AUTOSAR XML (schema 4-0-3)
package /ComponentTypes
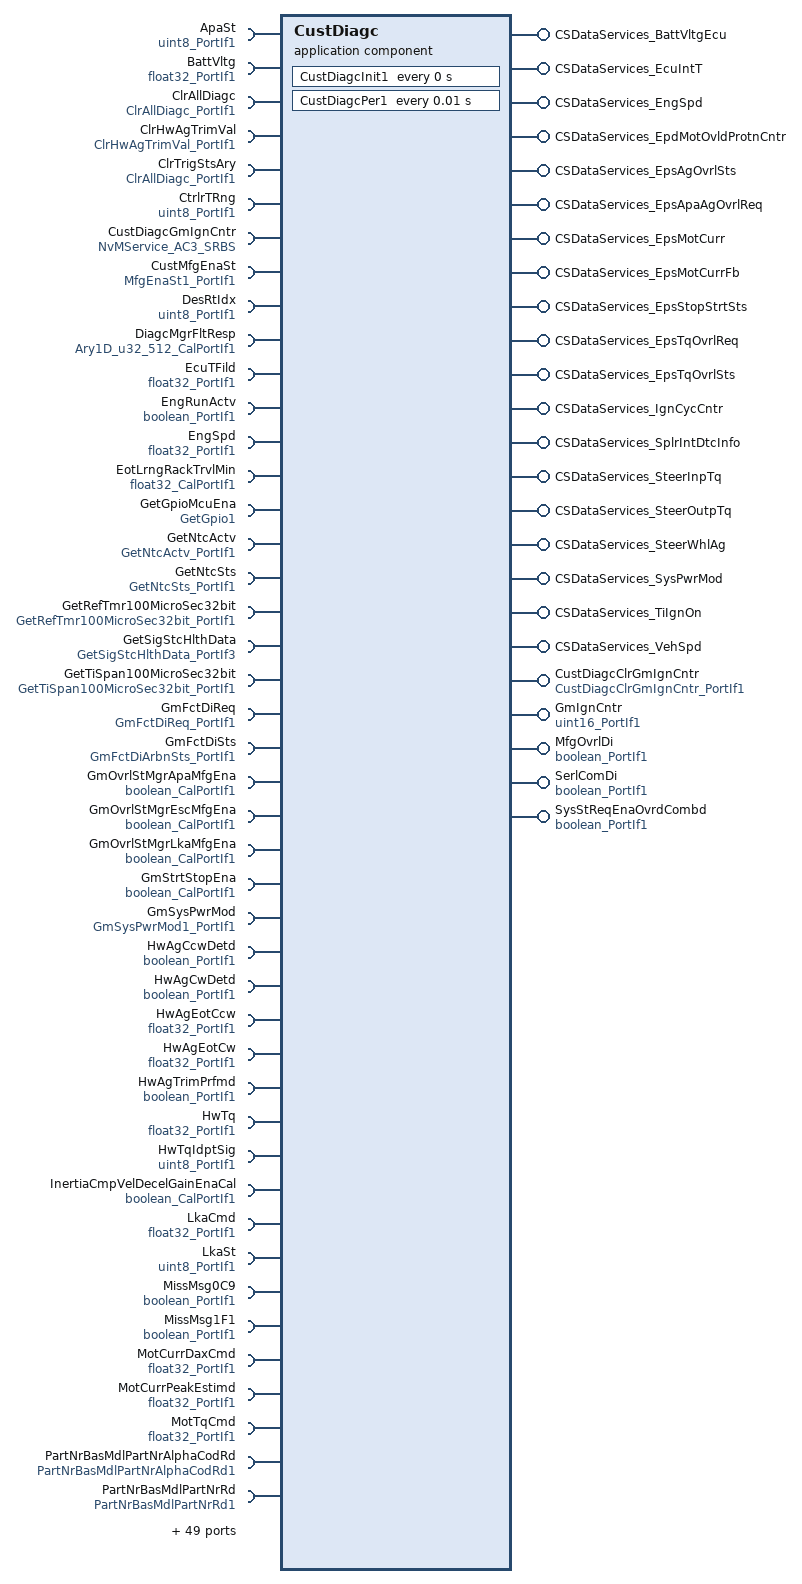
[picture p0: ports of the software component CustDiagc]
  application sw component type CustDiagc
    24 x provide port:
      CSDataServices_BattVltgEcu: server-com-spec{operation=ReadData, queue-length=1}, provided-interface=CSDataServices_BattVltgEcu
      CSDataServices_EcuIntT: server-com-spec{operation=ReadData, queue-length=1}, provided-interface=CSDataServices_EcuIntT
      CSDataServices_EngSpd: server-com-spec{operation=ReadData, queue-length=1}, provided-interface=CSDataServices_EngSpd
      CSDataServices_EpdMotOvldProtnCntr: server-com-spec{operation=ReadData, queue-length=1}, provided-interface=CSDataServices_EpdMotOvldProtnCntr
      CSDataServices_EpsAgOvrlSts: server-com-spec{operation=ReadData, queue-length=1}, provided-interface=CSDataServices_EpsAgOvrlSts
      CSDataServices_EpsApaAgOvrlReq: server-com-spec{operation=ReadData, queue-length=1}, provided-interface=CSDataServices_EpsApaAgOvrlReq
      CSDataServices_EpsMotCurr: server-com-spec{operation=ReadData, queue-length=1}, provided-interface=CSDataServices_EpsMotCurr
      CSDataServices_EpsMotCurrFb: server-com-spec{operation=ReadData, queue-length=1}, provided-interface=CSDataServices_EpsMotCurrFb
      CSDataServices_EpsStopStrtSts: server-com-spec{operation=ReadData, queue-length=1}, provided-interface=CSDataServices_EpsStopStrtSts
      CSDataServices_EpsTqOvrlReq: server-com-spec{operation=ReadData, queue-length=1}, provided-interface=CSDataServices_EpsTqOvrlReq
      CSDataServices_EpsTqOvrlSts: server-com-spec{operation=ReadData, queue-length=1}, provided-interface=CSDataServices_EpsTqOvrlSts
      CSDataServices_IgnCycCntr: server-com-spec{operation=ReadData, queue-length=1}, provided-interface=CSDataServices_IgnCycCntr
      CSDataServices_SplrIntDtcInfo: server-com-spec{operation=ReadData, queue-length=1}, provided-interface=CSDataServices_SplrIntDtcInfo
      CSDataServices_SteerInpTq: server-com-spec{operation=ReadData, queue-length=1}, provided-interface=CSDataServices_SteerInpTq
      CSDataServices_SteerOutpTq: server-com-spec{operation=ReadData, queue-length=1}, provided-interface=CSDataServices_SteerOutpTq
      CSDataServices_SteerWhlAg: server-com-spec{operation=ReadData, queue-length=1}, provided-interface=CSDataServices_SteerWhlAg
      CSDataServices_SysPwrMod: server-com-spec{operation=ReadData, queue-length=1}, provided-interface=CSDataServices_SysPwrMod
      CSDataServices_TiIgnOn: server-com-spec{operation=ReadData, queue-length=1}, provided-interface=CSDataServices_TiIgnOn
      CSDataServices_VehSpd: server-com-spec{operation=ReadData, queue-length=1}, provided-interface=CSDataServices_VehSpd
      CustDiagcClrGmIgnCntr: server-com-spec{operation=Oper, queue-length=1}, provided-interface=CustDiagcClrGmIgnCntr_PortIf1
      GmIgnCntr: nonqueued-sender-com-spec{data-element=Val, init-value=0}, provided-interface=uint16_PortIf1
      MfgOvrlDi: nonqueued-sender-com-spec{data-element=Logl, init-value=0}, provided-interface=boolean_PortIf1
      SerlComDi: nonqueued-sender-com-spec{data-element=Logl, init-value=0}, provided-interface=boolean_PortIf1
      SysStReqEnaOvrdCombd: nonqueued-sender-com-spec{data-element=Logl, init-value=0}, provided-interface=boolean_PortIf1
    93 x require port:
      ApaSt: nonqueued-receiver-com-spec{data-element=Val, filter=data-filter-type=ALWAYS, init-value=0}, required-interface=uint8_PortIf1
      BattVltg: nonqueued-receiver-com-spec{data-element=Val, filter=data-filter-type=ALWAYS, init-value=0}, required-interface=float32_PortIf1
      ClrAllDiagc: required-interface=ClrAllDiagc_PortIf1
      ClrHwAgTrimVal: required-interface=ClrHwAgTrimVal_PortIf1
      ClrTrigStsAry: required-interface=ClrAllDiagc_PortIf1
      CtrlrTRng: nonqueued-receiver-com-spec{data-element=Val, filter=data-filter-type=ALWAYS, init-value=0}, required-interface=uint8_PortIf1
      CustDiagcGmIgnCntr: required-interface=NvMService_AC3_SRBS
      CustMfgEnaSt: nonqueued-receiver-com-spec{data-element=Val, filter=data-filter-type=ALWAYS, init-value=0}, required-interface=MfgEnaSt1_PortIf1
      DesRtIdx: nonqueued-receiver-com-spec{data-element=Val, filter=data-filter-type=ALWAYS, init-value=0}, required-interface=uint8_PortIf1
      DiagcMgrFltResp: parameter-require-com-spec{init-value=[0, 2147487488, 2147487488, 2147487488, 2147487488, 2147487488, 2147487488, 2147487488, 2147487488, 2147487488, 2147487488, 2147487488, 2147487488, 2147487488, 2147487488, 2147487488, 2147487488, 2147487488, 2147487488, 2147487488, 2147487488, 2147487488, 2147487488, 2147487488, 2147487488, 2147487488, 2147487488, 2147487488, 2147487488, 2147487488, 2147487488, 2147487488, 2147487488, 2147487488, 2147487488, 2147487488, 2147487488, 2147487488, 2147487488, 2147487488, 2147487488, 2147487488, 2147487488, 2147487488, 2147487488, 2147487488, 2147487488, 2147487488, 2147487488, 2147487488, 2147487488, 2147487488, 2147487488, 2147487488, 2147487488, 2147487488, 2147487488, 2147487488, 2147487488, 2147487488, 2147487488, 2147487488, 2147487488, 2147487488, 2147487488, 2147487488, 2147487488, 2147487488, 2147487488, 2147487488, 2147487488, 2147487488, 2147487488, 2147487488, 2147487488, 2147487488, 2147487488, 2147487488, 2147487488, 2147487488, 2147487488, 2147487488, 2147487488, 2147487488, 2147487488, 2147487488, 2147487488, 2147487488, 2147487488, 2147487488, 2147487488, 2147487488, 2147487488, 2147487488, 2147487488, 2147487488, 2147487488, 2147487488, 2147487488, 2147487488, 2147487488, 2147487488, 2147487488, 2147487488, 2147487488, 2147487488, 2147487488, 2147487488, 2147487488, 2147487488, 2147487488, 2147487488, 2147487488, 2147487488, 2147487488, 2147487488, 2147487488, 2147487488, 2147487488, 2147487488, 2147487488, 2147487488, 2147487488, 2147487488, 2147487488, 2147487488, 2147487488, 2147487488, 2147487488, 2147487488, 2147487488, 2147487488, 2147487488, 2147487488, 2147487488, 2147487488, 2147487488, 2147487488, 2147487488, 2147487488, 2147487488, 2147487488, 2147487488, 2147487488, 2147487488, 2147487488, 2147487488, 2147487488, 2147487488, 2147487488, 2147487488, 2147487488, 2147487488, 2147487488, 2147487488, 2147487488, 2147487488, 2147487488, 2147487488, 2147487488, 2147487488, 2147487488, 2147487488, 2147487488, 2147487488, 2147487488, 2147487488, 2147487488, 2147487488, 2147487488, 2147487488, 2147487488, 2147487488, 2147487488, 2147487488, 2147487488, 2147487488, 2147487488, 2147487488, 2147487488, 2147487488, 2147487488, 2147487488, 2147487488, 2147487488, 2147487488, 2147487488, 2147487488, 2147487488, 2147487488, 2147487488, 2147487488, 2147487488, 2147487488, 2147487488, 2147487488, 2147487488, 2147487488, 2147487488, 2147487488, 2147487488, 2147487488, 2147487488, 2147487488, 2147487488, 2147487488, 2147487488, 2147487488, 2147487488, 2147487488, 2147487488, 2147487488, 2147487488, 2147487488, 2147487488, 2147487488, 2147487488, 2147487488, 2147487488, 2147487488, 2147487488, 2147487488, 2147487488, 2147487488, 2147487488, 2147487488, 2147487488, 2147487488, 2147487488, 2147487488, 2147487488, 2147487488, 2147487488, 2147487488, 2147487488, 2147487488, 2147487488, 2147487488, 2147487488, 2147487488, 2147487488, 2147487488, 2147487488, 2147487488, 2147487488, 2147487488, 2147487488, 2147487488, 2147487488, 2147487488, 2147487488, 2147487488, 2147487488, 2147487488, 2147487488, 2147487488, 2147487488, 2147487488, 2147487488, 2147487488, 2147487488, 2147487488, 2147487488, 2147487488, 2147487488, 2147487488, 2147487488, 2147487488, 2147487488, 2147487488, 2147487488, 2147487488, 2147487488, 2147487488, 2147487488, 2147487488, 2147487488, 2147487488, 2147487488, 2147487488, 2147487488, 2147487488, 2147487488, 2147487488, 2147487488, 2147487488, 2147487488, 2147487488, 2147487488, 2147487488, 2147487488, 2147487488, 2147487488, 2147487488, 2147487488, 2147487488, 2147487488, 2147487488, 2147487488, 2147487488, 2147487488, 2147487488, 2147487488, 2147487488, 2147487488, 2147487488, 2147487488, 2147487488, 2147487488, 2147487488, 2147487488, 2147487488, 2147487488, 2147487488, 2147487488, 2147487488, 2147487488, 2147487488, 2147487488, 2147487488, 2147487488, 2147487488, 2147487488, 2147487488, 2147487488, 2147487488, 2147487488, 2147487488, 2147487488, 2147487488, 2147487488, 2147487488, 2147487488, 2147487488, 2147487488, 2147487488, 2147487488, 2147487488, 2147487488, 2147487488, 2147487488, 2147487488, 2147487488, 2147487488, 2147487488, 2147487488, 2147487488, 2147487488, 2147487488, 2147487488, 2147487488, 2147487488, 2147487488, 2147487488, 2147487488, 2147487488, 2147487488, 2147487488, 2147487488, 2147487488, 2147487488, 2147487488, 2147487488, 2147487488, 2147487488, 2147487488, 2147487488, 2147487488, 2147487488, 2147487488, 2147487488, 2147487488, 2147487488, 2147487488, 2147487488, 2147487488, 2147487488, 2147487488, 2147487488, 2147487488, 2147487488, 2147487488, 2147487488, 2147487488, 2147487488, 2147487488, 2147487488, 2147487488, 2147487488, 2147487488, 2147487488, 2147487488, 2147487488, 2147487488, 2147487488, 2147487488, 2147487488, 2147487488, 2147487488, 2147487488, 2147487488, 2147487488, 2147487488, 2147487488, 2147487488, 2147487488, 2147487488, 2147487488, 2147487488, 2147487488, 2147487488, 2147487488, 2147487488, 2147487488, 2147487488, 2147487488, 2147487488, 2147487488, 2147487488, 2147487488, 2147487488, 2147487488, 2147487488, 2147487488, 2147487488, 2147487488, 2147487488, 2147487488, 2147487488, 2147487488, 2147487488, 2147487488, 2147487488, 2147487488, 2147487488, 2147487488, 2147487488, 2147487488, 2147487488, 2147487488, 2147487488, 2147487488, 2147487488, 2147487488, 2147487488, 2147487488, 2147487488, 2147487488, 2147487488, 2147487488, 2147487488, 2147487488, 2147487488, 2147487488, 2147487488, 2147487488, 2147487488, 2147487488, 2147487488, 2147487488, 2147487488, 2147487488, 2147487488, 2147487488, 2147487488, 2147487488, 2147487488, 2147487488, 2147487488, 2147487488, 2147487488, 2147487488, 2147487488, 2147487488, 2147487488, 2147487488, 2147487488, 2147487488, 2147487488, 2147487488, 2147487488, 2147487488, 2147487488, 2147487488, 2147487488, 2147487488, 2147487488, 2147487488, 2147487488, 2147487488, 2147487488, 2147487488, 2147487488, 2147487488, 2147487488, 2147487488, 2147487488, 2147487488, 2147487488, 2147487488, 2147487488, 2147487488, 2147487488, 2147487488, 2147487488, 2147487488, 2147487488, 2147487488, 2147487488, 2147487488, 2147487488, 2147487488], parameter=Ary1D}, required-interface=Ary1D_u32_512_CalPortIf1
      EcuTFild: nonqueued-receiver-com-spec{data-element=Val, filter=data-filter-type=ALWAYS, init-value=0}, required-interface=float32_PortIf1
      EngRunActv: nonqueued-receiver-com-spec{data-element=Logl, filter=data-filter-type=ALWAYS, init-value=0}, required-interface=boolean_PortIf1
      EngSpd: nonqueued-receiver-com-spec{data-element=Val, filter=data-filter-type=ALWAYS, init-value=0}, required-interface=float32_PortIf1
      EotLrngRackTrvlMin: parameter-require-com-spec{init-value=400, parameter=Val}, required-interface=float32_CalPortIf1
      GetGpioMcuEna: required-interface=GetGpio1
      GetNtcActv: required-interface=GetNtcActv_PortIf1
      GetNtcSts: required-interface=GetNtcSts_PortIf1
      GetRefTmr100MicroSec32bit: required-interface=GetRefTmr100MicroSec32bit_PortIf1
      GetSigStcHlthData: required-interface=GetSigStcHlthData_PortIf3
      GetTiSpan100MicroSec32bit: required-interface=GetTiSpan100MicroSec32bit_PortIf1
      GmFctDiReq: required-interface=GmFctDiReq_PortIf1
      GmFctDiSts: nonqueued-receiver-com-spec{data-element=Val, filter=data-filter-type=ALWAYS, init-value=0}, required-interface=GmFctDiArbnSts_PortIf1
      GmOvrlStMgrApaMfgEna: parameter-require-com-spec{init-value=0, parameter=Logl}, required-interface=boolean_CalPortIf1
      GmOvrlStMgrEscMfgEna: parameter-require-com-spec{init-value=0, parameter=Logl}, required-interface=boolean_CalPortIf1
      GmOvrlStMgrLkaMfgEna: parameter-require-com-spec{init-value=0, parameter=Logl}, required-interface=boolean_CalPortIf1
      GmStrtStopEna: parameter-require-com-spec{init-value=1, parameter=Logl}, required-interface=boolean_CalPortIf1
      GmSysPwrMod: nonqueued-receiver-com-spec{data-element=Val, filter=data-filter-type=ALWAYS, init-value=0}, required-interface=GmSysPwrMod1_PortIf1
      HwAgCcwDetd: nonqueued-receiver-com-spec{data-element=Logl, filter=data-filter-type=ALWAYS, init-value=0}, required-interface=boolean_PortIf1
      HwAgCwDetd: nonqueued-receiver-com-spec{data-element=Logl, filter=data-filter-type=ALWAYS, init-value=0}, required-interface=boolean_PortIf1
      HwAgEotCcw: nonqueued-receiver-com-spec{data-element=Val, filter=data-filter-type=ALWAYS, init-value=-360}, required-interface=float32_PortIf1
      HwAgEotCw: nonqueued-receiver-com-spec{data-element=Val, filter=data-filter-type=ALWAYS, init-value=360}, required-interface=float32_PortIf1
      HwAgTrimPrfmd: nonqueued-receiver-com-spec{data-element=Logl, filter=data-filter-type=ALWAYS, init-value=0}, required-interface=boolean_PortIf1
      HwTq: nonqueued-receiver-com-spec{data-element=Val, filter=data-filter-type=ALWAYS, init-value=0}, required-interface=float32_PortIf1
      HwTqIdptSig: nonqueued-receiver-com-spec{data-element=Val, filter=data-filter-type=ALWAYS, init-value=4}, required-interface=uint8_PortIf1
      InertiaCmpVelDecelGainEnaCal: parameter-require-com-spec{init-value=0, parameter=Logl}, required-interface=boolean_CalPortIf1
      LkaCmd: nonqueued-receiver-com-spec{data-element=Val, filter=data-filter-type=ALWAYS, init-value=0}, required-interface=float32_PortIf1
      LkaSt: nonqueued-receiver-com-spec{data-element=Val, filter=data-filter-type=ALWAYS, init-value=0}, required-interface=uint8_PortIf1
      MissMsg0C9: nonqueued-receiver-com-spec{data-element=Logl, filter=data-filter-type=ALWAYS, init-value=0}, required-interface=boolean_PortIf1
      MissMsg1F1: nonqueued-receiver-com-spec{data-element=Logl, filter=data-filter-type=ALWAYS, init-value=0}, required-interface=boolean_PortIf1
      MotCurrDaxCmd: nonqueued-receiver-com-spec{data-element=Val, filter=data-filter-type=ALWAYS, init-value=0}, required-interface=float32_PortIf1
      MotCurrPeakEstimd: nonqueued-receiver-com-spec{data-element=Val, filter=data-filter-type=ALWAYS, init-value=0}, required-interface=float32_PortIf1
      MotTqCmd: nonqueued-receiver-com-spec{data-element=Val, filter=data-filter-type=ALWAYS, init-value=0}, required-interface=float32_PortIf1
      PartNrBasMdlPartNrAlphaCodRd: required-interface=PartNrBasMdlPartNrAlphaCodRd1
      PartNrBasMdlPartNrRd: required-interface=PartNrBasMdlPartNrRd1
      PartNrCalProgdStsRd: required-interface=PartNrCalProgdStsRd1
      PartNrCalProgdStsWr: required-interface=PartNrCalProgdStsWr1
      PartNrCcaMfgTrakgRd: required-interface=PartNrCcaMfgTrakgRd1
      PartNrCmpdVehPartnProdtStructRd: required-interface=PartNrCmpdVehPartnProdtStructRd1
      PartNrCtrlPidKeyChk: required-interface=PartNrCtrlPidKeyChk1
      PartNrCtrlPidKeyWr: required-interface=PartNrCtrlPidKeyWr1
      PartNrCtrlPidSeedRd: required-interface=PartNrCtrlPidSeedRd1
      PartNrCtrlPidSeedUpprByteWr: required-interface=PartNrCtrlPidSeedUpprByteWr1
      PartNrCustMfgEnaCntrRd: required-interface=PartNrCustMfgEnaCntrRd1
      PartNrCustMfgEnaCntrWr: required-interface=PartNrCustMfgEnaCntrWr1
      PartNrDataUniversalNrSysIdRd: required-interface=PartNrDataUniversalNrSysIdRd1
      PartNrEcuIdRd: required-interface=PartNrEcuIdRd_PortIf1
      PartNrEndMdlPartNrAlphaCodRd: required-interface=PartNrEndMdlPartNrAlphaCodRd1
      PartNrEndMdlPartNrAlphaCodWr: required-interface=PartNrEndMdlPartNrAlphaCodWr1
      PartNrEndMdlPartNrRd: required-interface=PartNrEndMdlPartNrRd1
      PartNrEndMdlPartNrWr: required-interface=PartNrEndMdlPartNrWr1
      PartNrGmLanIdRd: required-interface=PartNrGmLanIdRd1
      PartNrLstRepairShopCodRd: required-interface=PartNrLstRepairShopCodRd1
      PartNrNxtrMfgTrakgRd: required-interface=PartNrNxtrMfgTrakgRd1
      PartNrNxtrMfgTrakgWr: required-interface=PartNrNxtrMfgTrakgWr1
      PartNrProgmDateRd: required-interface=PartNrProgmDateRd1
      PartNrProgmDateWr: required-interface=PartNrProgmDateWr1
      PartNrProgmSessionKeyChk: required-interface=PartNrProgmSessionKeyChk1
      PartNrProgmSessionSeedRd: required-interface=PartNrProgmSessionSeedRd1
      PartNrRepairShopCodRd: required-interface=PartNrRepairShopCodRd1
      PartNrRepairShopCodWr: required-interface=PartNrRepairShopCodWr1
      PartNrSecuBypAuthnRd: required-interface=PartNrSecuBypAuthnRd_PortIf1
      PartNrSecuBypAuthnWr: required-interface=PartNrSecuBypAuthnWr_PortIf1
      PartNrSysCodVersNrRd: required-interface=PartNrSysCodVersNrRd1
      PartNrSysCodVersNrWr: required-interface=PartNrSysCodVersNrWr1
      PartNrSysNameRd: required-interface=PartNrSysNameRd1
      PartNrSysNameWr: required-interface=PartNrSysNameWr1
      PartNrVinDataRd: required-interface=PartNrVinDataRd1
      PartNrVinDataWr: required-interface=PartNrVinDataWr1
      PinionAg: nonqueued-receiver-com-spec{data-element=Val, filter=data-filter-type=ALWAYS, init-value=0}, required-interface=float32_PortIf1
      PinionAgConf: nonqueued-receiver-com-spec{data-element=Val, filter=data-filter-type=ALWAYS, init-value=0}, required-interface=float32_PortIf1
      PullCmpActvEna: parameter-require-com-spec{init-value=1, parameter=Logl}, required-interface=boolean_CalPortIf1
      RtnMaxHwAgCwAndCcw: required-interface=RtnMaxHwAgCwAndCcw_PortIf1
      SteerWhlAgReqTarAg: nonqueued-receiver-com-spec{data-element=Val, filter=data-filter-type=ALWAYS, init-value=0}, required-interface=float32_PortIf1
      StrtStopSt: nonqueued-receiver-com-spec{data-element=Val, filter=data-filter-type=ALWAYS, init-value=0}, required-interface=uint8_PortIf1
      SysPwrMod: nonqueued-receiver-com-spec{data-element=Val, filter=data-filter-type=ALWAYS, init-value=0}, required-interface=GmSysPwrMod1_PortIf1
      SysSt: nonqueued-receiver-com-spec{data-element=Val, filter=data-filter-type=ALWAYS, init-value=3}, required-interface=SysSt1
      SysStReqEnaOvrdNxtr: nonqueued-receiver-com-spec{data-element=Logl, filter=data-filter-type=ALWAYS, init-value=0}, required-interface=boolean_PortIf1
      ThermLimFlgCntr: nonqueued-receiver-com-spec{data-element=Val, filter=data-filter-type=ALWAYS, init-value=0}, required-interface=uint8_PortIf1
      UpdHwAgTrimVal: required-interface=UpdHwAgTrimVal_PortIf1
      VehSpd: nonqueued-receiver-com-spec{data-element=Val, filter=data-filter-type=ALWAYS, init-value=0}, required-interface=float32_PortIf1
      VehSpdVld: nonqueued-receiver-com-spec{data-element=Logl, filter=data-filter-type=ALWAYS, init-value=0}, required-interface=boolean_PortIf1
      VltgRng: nonqueued-receiver-com-spec{data-element=Val, filter=data-filter-type=ALWAYS, init-value=0}, required-interface=uint8_PortIf1
      WhlImbRejctnFctEna: parameter-require-com-spec{init-value=1, parameter=Logl}, required-interface=boolean_CalPortIf1
    behavior CustDiagc_InternalBehavior: data-type-mapping=Nexteer
      ar-typed-per-instance-memorys:
        18 x data, all with sw-calibration-access=READ-ONLY:
          CpidActv: type=boolean
          CustDiagcCtrlPidKeyAtmptCntr: type=uint8
          CustDiagcCtrlPidSeedKeyTmr: type=uint32
          CustDiagcCtrlPidSeedReqd: type=boolean
          CustDiagcCtrlPidSeedTmrActvd: type=boolean
          CustDiagcProgmSessionKeyAtmptCntr: type=uint8
          CustDiagcProgmSessionSeedKeyTmr: type=uint32
          CustDiagcProgmSessionSeedReqd: type=boolean
          CustDiagcProgmSessionSeedTmrActvd: type=boolean
          DtcNr: type=uint32
          GmDiCtrlPidTstRunng: type=boolean
          GmIgnCntr: type=uint16
          MsgCntxt: type=uint32
          PrevGmFctDiArbnSts: type=GmFctDiArbnSts1
          PrevSysPwrModRun: type=boolean
          Srv12LoopCntr: type=uint8
          SrvCntxt: type=uint8
          SysStReqEnaOvrdCust: type=boolean
      20 x operation invoked event:
        OIT_CSDataServices_BattVltgEcu_ReadData_CSDataServices_BattVltgEcu_ReadData: start-on-event=CSDataServices_BattVltgEcu_ReadData, operation=CSDataServices_BattVltgEcu.ReadData
        OIT_CSDataServices_EcuIntT_ReadData_CSDataServices_EcuIntT_ReadData: start-on-event=CSDataServices_EcuIntT_ReadData, operation=CSDataServices_EcuIntT.ReadData
        OIT_CSDataServices_EngSpd_ReadData_CSDataServices_EngSpd_ReadData: start-on-event=CSDataServices_EngSpd_ReadData, operation=CSDataServices_EngSpd.ReadData
        OIT_CSDataServices_EpdMotOvldProtnCntr_ReadData_CSDataServices_EpdMotOvldProtnCntr_ReadData: start-on-event=CSDataServices_EpdMotOvldProtnCntr_ReadData, operation=CSDataServices_EpdMotOvldProtnCntr.ReadData
        OIT_CSDataServices_EpsAgOvrlSts_ReadData_CSDataServices_EpsAgOvrlSts_ReadData: start-on-event=CSDataServices_EpsAgOvrlSts_ReadData, operation=CSDataServices_EpsAgOvrlSts.ReadData
        OIT_CSDataServices_EpsApaAgOvrlReq_ReadData_CSDataServices_EpsApaAgOvrlReq_ReadData: start-on-event=CSDataServices_EpsApaAgOvrlReq_ReadData, operation=CSDataServices_EpsApaAgOvrlReq.ReadData
        OIT_CSDataServices_EpsMotCurr_ReadData_CSDataServices_EpsMotCurr_ReadData: start-on-event=CSDataServices_EpsMotCurr_ReadData, operation=CSDataServices_EpsMotCurr.ReadData
        OIT_CSDataServices_EpsMotCurrFb_ReadData_CSDataServices_EpsMotCurrFb_ReadData: start-on-event=CSDataServices_EpsMotCurrFb_ReadData, operation=CSDataServices_EpsMotCurrFb.ReadData
        OIT_CSDataServices_EpsStopStrtSts_ReadData_CSDataServices_EpsStopStrtSts_ReadData: start-on-event=CSDataServices_EpsStopStrtSts_ReadData, operation=CSDataServices_EpsStopStrtSts.ReadData
        OIT_CSDataServices_EpsTqOvrlReq_ReadData_CSDataServices_EpsTqOvrlReq_ReadData: start-on-event=CSDataServices_EpsTqOvrlReq_ReadData, operation=CSDataServices_EpsTqOvrlReq.ReadData
        OIT_CSDataServices_EpsTqOvrlSts_ReadData_CSDataServices_EpsTqOvrlSts_ReadData: start-on-event=CSDataServices_EpsTqOvrlSts_ReadData, operation=CSDataServices_EpsTqOvrlSts.ReadData
        OIT_CSDataServices_IgnCycCntr_ReadData_CSDataServices_IgnCycCntr_ReadData: start-on-event=CSDataServices_IgnCycCntr_ReadData, operation=CSDataServices_IgnCycCntr.ReadData
        OIT_CSDataServices_SplrIntDtcInfo_ReadData_CSDataServices_SplrIntDtcInfo_ReadData: start-on-event=CSDataServices_SplrIntDtcInfo_ReadData, operation=CSDataServices_SplrIntDtcInfo.ReadData
        OIT_CSDataServices_SteerInpTq_ReadData_CSDataServices_SteerInpTq_ReadData: start-on-event=CSDataServices_SteerInpTq_ReadData, operation=CSDataServices_SteerInpTq.ReadData
        OIT_CSDataServices_SteerOutpTq_ReadData_CSDataServices_SteerOutpTq_ReadData: start-on-event=CSDataServices_SteerOutpTq_ReadData, operation=CSDataServices_SteerOutpTq.ReadData
        OIT_CSDataServices_SteerWhlAg_ReadData_CSDataServices_SteerWhlAg_ReadData: start-on-event=CSDataServices_SteerWhlAg_ReadData, operation=CSDataServices_SteerWhlAg.ReadData
        OIT_CSDataServices_SysPwrMod_ReadData_CSDataServices_SysPwrMod_ReadData: start-on-event=CSDataServices_SysPwrMod_ReadData, operation=CSDataServices_SysPwrMod.ReadData
        OIT_CSDataServices_TiIgnOn_ReadData_CSDataServices_TiIgnOn_ReadData: start-on-event=CSDataServices_TiIgnOn_ReadData, operation=CSDataServices_TiIgnOn.ReadData
        OIT_CSDataServices_VehSpd_ReadData_CSDataServices_VehSpd_ReadData: start-on-event=CSDataServices_VehSpd_ReadData, operation=CSDataServices_VehSpd.ReadData
        OIT_CustDiagcClrGmIgnCntr_Oper_CustDiagcClrGmIgnCntr_Oper: start-on-event=CustDiagcClrGmIgnCntr_Oper, operation=CustDiagcClrGmIgnCntr.Oper
      timing event CustDiagc_InitEvent: start-on-event=CustDiagcInit1, period=0
      timing event TMT_CustDiagcPer1: start-on-event=CustDiagcPer1, period=0.01
      22 x runnable:
        CSDataServices_BattVltgEcu_ReadData
          data-receive-point-by-arguments:
            access REC_BattVltg_Val: accessed-variable=BattVltg.Val
        CSDataServices_EcuIntT_ReadData
          data-receive-point-by-arguments:
            access REC_EcuTFild_Val: accessed-variable=EcuTFild.Val
        CSDataServices_EngSpd_ReadData
          data-receive-point-by-arguments:
            access REC_EngSpd_Val: accessed-variable=EngSpd.Val
            access REC_MissMsg0C9_Logl: accessed-variable=MissMsg0C9.Logl
        CSDataServices_EpdMotOvldProtnCntr_ReadData
          data-receive-point-by-arguments:
            access REC_ThermLimFlgCntr_Val: accessed-variable=ThermLimFlgCntr.Val
        CSDataServices_EpsAgOvrlSts_ReadData
          data-receive-point-by-arguments:
            access REC_ApaSt_Val: accessed-variable=ApaSt.Val
        CSDataServices_EpsApaAgOvrlReq_ReadData
          data-receive-point-by-arguments:
            access REC_SteerWhlAgReqTarAg_Val: accessed-variable=SteerWhlAgReqTarAg.Val
        CSDataServices_EpsMotCurr_ReadData
          data-receive-point-by-arguments:
            access REC_MotCurrDaxCmd_Val: accessed-variable=MotCurrDaxCmd.Val
        CSDataServices_EpsMotCurrFb_ReadData
          data-receive-point-by-arguments:
            access REC_MotCurrPeakEstimd_Val: accessed-variable=MotCurrPeakEstimd.Val
        CSDataServices_EpsStopStrtSts_ReadData
          data-receive-point-by-arguments:
            access REC_StrtStopSt_Val: accessed-variable=StrtStopSt.Val
        CSDataServices_EpsTqOvrlReq_ReadData
          data-receive-point-by-arguments:
            access REC_LkaCmd_Val: accessed-variable=LkaCmd.Val
        CSDataServices_EpsTqOvrlSts_ReadData
          data-receive-point-by-arguments:
            access REC_LkaSt_Val: accessed-variable=LkaSt.Val
        CSDataServices_IgnCycCntr_ReadData
        CSDataServices_SplrIntDtcInfo_ReadData
          sync call SC_GetNtcActv_Oper: operation=GetNtcActv.Oper, timeout=0
          sync call SC_GetNtcSts_Oper: operation=GetNtcSts.Oper, timeout=0
        CSDataServices_SteerInpTq_ReadData
          data-receive-point-by-arguments:
            access REC_HwTq_Val: accessed-variable=HwTq.Val
        CSDataServices_SteerOutpTq_ReadData
          data-receive-point-by-arguments:
            access REC_MotTqCmd_Val: accessed-variable=MotTqCmd.Val
        CSDataServices_SteerWhlAg_ReadData
          data-receive-point-by-arguments:
            access REC_PinionAg_Val: accessed-variable=PinionAg.Val
        CSDataServices_SysPwrMod_ReadData
          data-receive-point-by-arguments:
            access REC_GmSysPwrMod_Val: accessed-variable=GmSysPwrMod.Val
            access REC_MissMsg1F1_Logl: accessed-variable=MissMsg1F1.Logl
        CSDataServices_TiIgnOn_ReadData
          sync call SC_GetRefTmr100MicroSec32bit_Oper: operation=GetRefTmr100MicroSec32bit.Oper, timeout=0
        CSDataServices_VehSpd_ReadData
          data-receive-point-by-arguments:
            access REC_VehSpd_Val: accessed-variable=VehSpd.Val
        CustDiagcClrGmIgnCntr_Oper
          sync call SC_CustDiagcGmIgnCntr_SetRamBlockStatus: operation=CustDiagcGmIgnCntr.SetRamBlockStatus, timeout=0
        CustDiagcInit1
          data-receive-point-by-arguments:
            31 x access:
              REC_ApaSt_Val: accessed-variable=ApaSt.Val
              REC_BattVltg_Val: accessed-variable=BattVltg.Val
              REC_CtrlrTRng_Val_1: accessed-variable=CtrlrTRng.Val
              REC_DesRtIdx_Val: accessed-variable=DesRtIdx.Val
              REC_EcuTFild_Val: accessed-variable=EcuTFild.Val
              REC_EngRunActv_Logl: accessed-variable=EngRunActv.Logl
              REC_EngSpd_Val: accessed-variable=EngSpd.Val
              REC_HwAgCcwDetd_Logl: accessed-variable=HwAgCcwDetd.Logl
              REC_HwAgCwDetd_Logl: accessed-variable=HwAgCwDetd.Logl
              REC_HwAgEotCcw_Val: accessed-variable=HwAgEotCcw.Val
              REC_HwAgEotCw_Val: accessed-variable=HwAgEotCw.Val
              REC_HwAgTrimPrfmd_Logl: accessed-variable=HwAgTrimPrfmd.Logl
              REC_HwTq_Val: accessed-variable=HwTq.Val
              REC_HwTqIdptSig_Val: accessed-variable=HwTqIdptSig.Val
              REC_LkaCmd_Val: accessed-variable=LkaCmd.Val
              REC_LkaSt_Val: accessed-variable=LkaSt.Val
              REC_MfgEnaSt_Val: accessed-variable=CustMfgEnaSt.Val
              REC_MissMsg0C9_Logl: accessed-variable=MissMsg0C9.Logl
              REC_MotCurrDaxCmd_Val: accessed-variable=MotCurrDaxCmd.Val
              REC_MotCurrPeakEstimd_Val: accessed-variable=MotCurrPeakEstimd.Val
              REC_MotTqCmd_Val: accessed-variable=MotTqCmd.Val
              REC_PinionAg_Val: accessed-variable=PinionAg.Val
              REC_PinionAgConf_Val: accessed-variable=PinionAgConf.Val
              REC_SteerWhlAgReqTarAg_Val: accessed-variable=SteerWhlAgReqTarAg.Val
              REC_StrtStopSt_Val: accessed-variable=StrtStopSt.Val
              REC_SysPwrMod_Val: accessed-variable=SysPwrMod.Val
              REC_SysSt_Val: accessed-variable=SysSt.Val
              REC_ThermLimFlgCntr_Val: accessed-variable=ThermLimFlgCntr.Val
              REC_VehSpd_Val: accessed-variable=VehSpd.Val
              REC_VehSpdVld_Logl: accessed-variable=VehSpdVld.Logl
              REC_VltgRng_Val: accessed-variable=VltgRng.Val
          data-send-points:
            access SEND_MfgOvrlDi_Logl: accessed-variable=MfgOvrlDi.Logl
            access SEND_SerlComDi_Logl: accessed-variable=SerlComDi.Logl
          46 x sync call, all with timeout=0:
            SC_ClrAllDiagc_Oper: operation=ClrAllDiagc.Oper
            SC_ClrHwAgTrimVal_Oper: operation=ClrHwAgTrimVal.Oper
            SC_ClrTrigStsAry_Oper: operation=ClrTrigStsAry.Oper
            SC_GetGpioMcuEna_Oper: operation=GetGpioMcuEna.Oper
            SC_GetRefTmr100MicroSec32bit_Oper: operation=GetRefTmr100MicroSec32bit.Oper
            SC_GetSigStcHlthData_Oper: operation=GetSigStcHlthData.Oper
            SC_GetTiSpan100MicroSec32bit_Oper: operation=GetTiSpan100MicroSec32bit.Oper
            SC_GmFctDiReq_Oper: operation=GmFctDiReq.Oper
            SC_PartNrBasMdlPartNrAlphaCodRd_Oper: operation=PartNrBasMdlPartNrAlphaCodRd.Oper
            SC_PartNrBasMdlPartNrRd_Oper: operation=PartNrBasMdlPartNrRd.Oper
            SC_PartNrCalProgdStsRd_Oper: operation=PartNrCalProgdStsRd.Oper
            SC_PartNrCalProgdStsWr_Oper: operation=PartNrCalProgdStsWr.Oper
            SC_PartNrCcaMfgTrakgRd_Oper: operation=PartNrCcaMfgTrakgRd.Oper
            SC_PartNrCmpdVehPartnProdtStructRd_Oper: operation=PartNrCmpdVehPartnProdtStructRd.Oper
            SC_PartNrCtrlPidKeyChk_Oper: operation=PartNrCtrlPidKeyChk.Oper
            SC_PartNrCtrlPidKeyWr_Oper: operation=PartNrCtrlPidKeyWr.Oper
            SC_PartNrCtrlPidSeedRd_Oper: operation=PartNrCtrlPidSeedRd.Oper
            SC_PartNrCtrlPidSeedUpprByteWr_Oper: operation=PartNrCtrlPidSeedUpprByteWr.Oper
            SC_PartNrCustMfgEnaCntrRd_Oper: operation=PartNrCustMfgEnaCntrRd.Oper
            SC_PartNrCustMfgEnaCntrWr_Oper: operation=PartNrCustMfgEnaCntrWr.Oper
            SC_PartNrDataUniversalNrSysIdRd_Oper: operation=PartNrDataUniversalNrSysIdRd.Oper
            SC_PartNrEcuIdRd_Oper: operation=PartNrEcuIdRd.Oper
            SC_PartNrEndMdlPartNrAlphaCodRd_Oper: operation=PartNrEndMdlPartNrAlphaCodRd.Oper
            SC_PartNrEndMdlPartNrAlphaCodWr_Oper: operation=PartNrEndMdlPartNrAlphaCodWr.Oper
            SC_PartNrEndMdlPartNrRd_Oper: operation=PartNrEndMdlPartNrRd.Oper
            SC_PartNrEndMdlPartNrWr_Oper: operation=PartNrEndMdlPartNrWr.Oper
            SC_PartNrGmLanIdRd_Oper: operation=PartNrGmLanIdRd.Oper
            SC_PartNrLstRepairShopCodRd_Oper: operation=PartNrLstRepairShopCodRd.Oper
            SC_PartNrNxtrMfgTrakgRd_Oper: operation=PartNrNxtrMfgTrakgRd.Oper
            SC_PartNrNxtrMfgTrakgWr_Oper: operation=PartNrNxtrMfgTrakgWr.Oper
            SC_PartNrProgmDateRd_Oper: operation=PartNrProgmDateRd.Oper
            SC_PartNrProgmDateWr_Oper: operation=PartNrProgmDateWr.Oper
            SC_PartNrProgmSessionKeyChk_Oper: operation=PartNrProgmSessionKeyChk.Oper
            SC_PartNrProgmSessionSeedRd_Oper: operation=PartNrProgmSessionSeedRd.Oper
            SC_PartNrRepairShopCodRd_Oper: operation=PartNrRepairShopCodRd.Oper
            SC_PartNrRepairShopCodWr_Oper: operation=PartNrRepairShopCodWr.Oper
            SC_PartNrSecuBypAuthnRd_Oper: operation=PartNrSecuBypAuthnRd.Oper
            SC_PartNrSecuBypAuthnWr_Oper: operation=PartNrSecuBypAuthnWr.Oper
            SC_PartNrSysCodVersNrRd_Oper: operation=PartNrSysCodVersNrRd.Oper
            SC_PartNrSysCodVersNrWr_Oper: operation=PartNrSysCodVersNrWr.Oper
            SC_PartNrSysNameRd_Oper: operation=PartNrSysNameRd.Oper
            SC_PartNrSysNameWr_Oper: operation=PartNrSysNameWr.Oper
            SC_PartNrVinDataRd_Oper: operation=PartNrVinDataRd.Oper
            SC_PartNrVinDataWr_Oper: operation=PartNrVinDataWr.Oper
            SC_RtnMaxHwAgCwAndCcw_Oper: operation=RtnMaxHwAgCwAndCcw.Oper
            SC_UpdHwAgTrimVal_Oper: operation=UpdHwAgTrimVal.Oper
        CustDiagcPer1
          data-receive-point-by-arguments:
            access REC_GmFctDiSts_Val: accessed-variable=GmFctDiSts.Val
            access REC_GmSysPwrMod_Val: accessed-variable=GmSysPwrMod.Val
            access REC_SysStReqEnaOvrdNxtr_Logl: accessed-variable=SysStReqEnaOvrdNxtr.Logl
          data-send-points:
            access SEND_GmIgnCntr_Val: accessed-variable=GmIgnCntr.Val
            access SEND_SysStReqEnaOvrdCombd_Logl: accessed-variable=SysStReqEnaOvrdCombd.Logl
          sync call SC_CustDiagcGmIgnCntr_SetRamBlockStatus: operation=CustDiagcGmIgnCntr.SetRamBlockStatus, timeout=0
      swc service dependency NvmGmIgnCntr: assigned-datas=role-based-data-assignment={role=ramBlock, used-data-element=GmIgnCntr}
        assigned-ports:
          port-prototype=CustDiagcGmIgnCntr, role=NvMService_AC3_SRBS
          port-prototype=CustDiagcGmIgnCntr, role=NvMService_AC3_SRBS
        service-needs:
          nv block needs NvmGmIgnCntr: n-data-sets=0, readonly=false, reliability=NO-PROTECTION, resistant-to-changed-sw=true, restore-at-start=true, store-at-shutdown=true, write-only-once=false, writing-frequency=0, writing-priority=LOW
  swc implementation CustDiagc_Implementation: behavior=CustDiagc_InternalBehavior
    code-descriptors:
      code Default: artifact-descriptors=autosar-engineering-object={short-label=Default, category=SWSRC}
